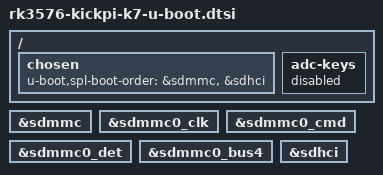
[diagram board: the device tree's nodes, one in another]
// SPDX-License-Identifier: GPL-2.0+
#include <dt-bindings/input/input.h>
#include "rk3576-u-boot.dtsi"

/ {
    chosen {
        u-boot,spl-boot-order = &sdmmc, &sdhci;
    };
    adc-keys { status = "disabled"; };
};

&sdmmc { bootph-all; };
&sdmmc0_clk { bootph-all; };
&sdmmc0_cmd { bootph-all; };
&sdmmc0_det { bootph-all; };
&sdmmc0_bus4 { bootph-all; };
&sdhci {
    /delete-property/ mmc-hs400-1_8v;
    /delete-property/ mmc-hs400-enhanced-strobe;
};
